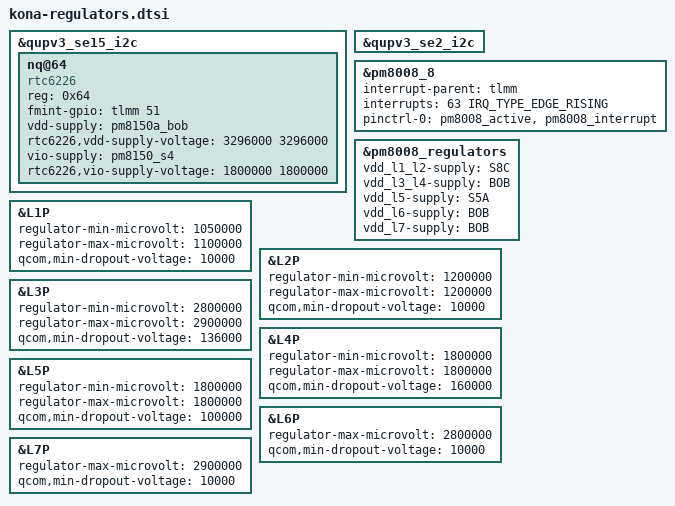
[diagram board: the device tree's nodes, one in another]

&qupv3_se15_i2c {
	status = "ok";
	nq@64 {
		compatible = "rtc6226";
		reg = <0x64>;
		fmint-gpio = <&tlmm 51 0>;
		vdd-supply = <&pm8150a_bob>;
		rtc6226,vdd-supply-voltage = <3296000 3296000>;
		vio-supply = <&pm8150_s4>;
		rtc6226,vio-supply-voltage = <1800000 1800000 >;
	};
};

&qupv3_se2_i2c {
	status = "ok";
	#include "../../pm8008.dtsi"
};

&pm8008_8 {
	/* PM8008 IRQ STAT */
	interrupt-parent = <&tlmm>;
	interrupts = <63 IRQ_TYPE_EDGE_RISING>;

	pinctrl-names = "default";
	pinctrl-0 = <&pm8008_active &pm8008_interrupt>;
};

&pm8008_regulators {
	vdd_l1_l2-supply = <&S8C>;
	vdd_l3_l4-supply = <&BOB>;
	vdd_l5-supply = <&S5A>;
	vdd_l6-supply = <&BOB>;
	vdd_l7-supply = <&BOB>;
};

&L1P {
	regulator-min-microvolt = <1050000>;
	regulator-max-microvolt = <1100000>;
	qcom,min-dropout-voltage = <10000>;
};

&L2P {
	regulator-min-microvolt = <1200000>;
	regulator-max-microvolt = <1200000>;
	qcom,min-dropout-voltage = <10000>;
};

&L3P {
	regulator-min-microvolt = <2800000>;
	regulator-max-microvolt = <2900000>;
	qcom,min-dropout-voltage = <136000>;
};

&L4P {
	regulator-min-microvolt = <1800000>;
	regulator-max-microvolt = <1800000>;
	qcom,min-dropout-voltage = <160000>;
};

&L5P {
	regulator-min-microvolt = <1800000>;
	regulator-max-microvolt = <1800000>;
	qcom,min-dropout-voltage = <100000>;
};

&L6P {
	regulator-max-microvolt = <2800000>;
	qcom,min-dropout-voltage = <10000>;
};

&L7P {
	regulator-max-microvolt = <2900000>;
	qcom,min-dropout-voltage = <10000>;
};
